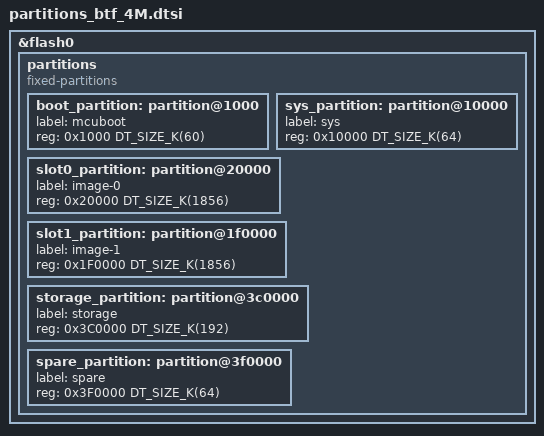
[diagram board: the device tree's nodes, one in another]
/*
 * SPDX-License-Identifier: Apache-2.0
 *
 * 4MB layout for a single-core (PROCPU-only) Matter application.
 *
 * Derived from Zephyr's partitions_0x1000_amp_4M.dtsi with the appcpu,
 * lpcore, scratch and coredump partitions deleted: we never enable the APP
 * CPU, and MCUboot (if/when OTA lands) would run overwrite-only, which
 * needs no scratch. That grows each app slot from 1344K to 1856K — Matter
 * does not fit in 1344K.
 *
 * The MVP boots via ESP Simple Boot and only uses slot0; slot1 and the
 * mcuboot partition are reserved so an OTA-capable layout needs no
 * repartitioning (and therefore no device re-provisioning) later.
 */

&flash0 {
	partitions {
		compatible = "fixed-partitions";
		#address-cells = <1>;
		#size-cells = <1>;

		boot_partition: partition@1000 {
			label = "mcuboot";
			reg = <0x1000 DT_SIZE_K(60)>;
		};

		/* Vestigial (inherited from the stock layout): its only consumer
		 * in the tree is the virtual-eFuse test mode
		 * (ESP32_EFUSE_VIRTUAL_KEEP_IN_FLASH), which we don't enable.
		 * Kept because this layout is on deployed boards -- reshuffling
		 * offsets would orphan the storage partition contents. The 8M C6
		 * layout drops it.
		 */
		sys_partition: partition@10000 {
			label = "sys";
			reg = <0x10000 DT_SIZE_K(64)>;
		};

		slot0_partition: partition@20000 {
			label = "image-0";
			reg = <0x20000 DT_SIZE_K(1856)>;
		};

		slot1_partition: partition@1f0000 {
			label = "image-1";
			reg = <0x1F0000 DT_SIZE_K(1856)>;
		};

		/* Zephyr settings/NVS: Matter fabrics + KVS, WiFi credentials,
		 * and the chip-fct provisioning keys (pairing code).
		 */
		storage_partition: partition@3c0000 {
			label = "storage";
			reg = <0x3C0000 DT_SIZE_K(192)>;
		};

		/* Future factory-data partition or coredump space. */
		spare_partition: partition@3f0000 {
			label = "spare";
			reg = <0x3F0000 DT_SIZE_K(64)>;
		};
	};
};

/* Remaining flash size is 0kB
 * Last used address is 0x3FFFFF
 */
